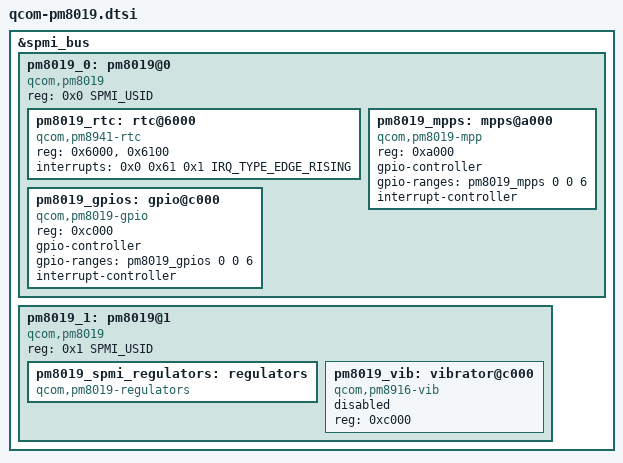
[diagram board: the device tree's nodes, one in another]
// SPDX-License-Identifier: GPL-2.0
/*
 * Copyright (c) 2020, Konrad Dybcio
 */

#include <dt-bindings/interrupt-controller/irq.h>
#include <dt-bindings/spmi/spmi.h>

&spmi_bus {
	pm8019_0: pm8019@0 {
		compatible = "qcom,pm8019", "qcom,spmi-pmic";
		reg = <0x0 SPMI_USID>;
		#address-cells = <1>;
		#size-cells = <0>;

		pm8019_rtc: rtc@6000 {
			compatible = "qcom,pm8941-rtc";
			reg = <0x6000>, <0x6100>;
			reg-names = "rtc", "alarm";
			interrupts = <0x0 0x61 0x1 IRQ_TYPE_EDGE_RISING>;
		};

		pm8019_mpps: mpps@a000 {
			compatible = "qcom,pm8019-mpp", "qcom,spmi-mpp";
			reg = <0xa000>;
			gpio-controller;
			#gpio-cells = <2>;
			gpio-ranges = <&pm8019_mpps 0 0 6>;
			interrupt-controller;
			#interrupt-cells = <2>;
		};

		pm8019_gpios: gpio@c000 {
			compatible = "qcom,pm8019-gpio", "qcom,spmi-gpio";
			reg = <0xc000>;
			gpio-controller;
			#gpio-cells = <2>;
			gpio-ranges = <&pm8019_gpios 0 0 6>;
			interrupt-controller;
			#interrupt-cells = <2>;
		};
	};

	pm8019_1: pm8019@1 {
		compatible = "qcom,pm8019", "qcom,spmi-pmic";
		reg = <0x1 SPMI_USID>;
		#address-cells = <1>;
		#size-cells = <0>;

		pm8019_spmi_regulators: regulators {
			compatible = "qcom,pm8019-regulators";
		};

		pm8019_vib: vibrator@c000 {
			compatible = "qcom,pm8916-vib";
			reg = <0xc000>;
			status = "disabled";
		};
	};
};
